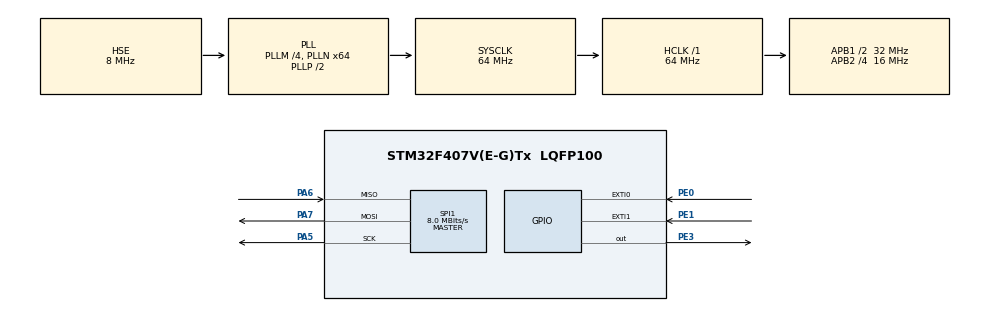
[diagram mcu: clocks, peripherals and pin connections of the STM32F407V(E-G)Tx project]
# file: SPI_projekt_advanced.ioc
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Mcu.Family=STM32F4
Mcu.Name=STM32F407V(E-G)Tx
Mcu.Package=LQFP100
NVIC.EXTI0_IRQn=true\:0\:0\:false\:false\:true\:true\:true\:true
NVIC.EXTI1_IRQn=true\:0\:0\:false\:false\:true\:true\:true\:true
NVIC.PriorityGroup=NVIC_PRIORITYGROUP_0
NVIC.SPI1_IRQn=true\:0\:0\:false\:false\:true\:true\:true\:true
PA5.Mode=Full_Duplex_Master
PA5.Signal=SPI1_SCK
PA6.Mode=Full_Duplex_Master
PA6.Signal=SPI1_MISO
PA7.Mode=Full_Duplex_Master
PA7.Signal=SPI1_MOSI
PE0.Signal=GPXTI0
PE1.Signal=GPXTI1
PE3.PinState=GPIO_PIN_SET
PE3.Signal=GPIO_Output
PH0-OSC_IN.Mode=HSE-External-Oscillator
PH0-OSC_IN.Signal=RCC_OSC_IN
PH1-OSC_OUT.Mode=HSE-External-Oscillator
PH1-OSC_OUT.Signal=RCC_OSC_OUT
ProjectManager.HeapSize=0x200
ProjectManager.StackSize=0x400
ProjectManager.TargetToolchain=STM32CubeIDE
RCC.48MHZClocksFreq_Value=18285714.285714287
RCC.AHBFreq_Value=64000000
RCC.APB1CLKDivider=RCC_HCLK_DIV2
RCC.APB1Freq_Value=32000000
RCC.APB1TimFreq_Value=64000000
RCC.APB2CLKDivider=RCC_HCLK_DIV4
RCC.APB2Freq_Value=16000000
RCC.APB2TimFreq_Value=32000000
RCC.CortexFreq_Value=64000000
RCC.HCLKFreq_Value=64000000
RCC.HSE_VALUE=8000000
RCC.HSI_VALUE=16000000
RCC.LSE_VALUE=32768
RCC.PLLM=4
RCC.PLLN=64
RCC.PLLQ=7
RCC.PLLSourceVirtual=RCC_PLLSOURCE_HSE
RCC.SYSCLKFreq_VALUE=64000000
RCC.SYSCLKSource=RCC_SYSCLKSOURCE_PLLCLK
RCC.VCOOutputFreq_Value=128000000
SPI1.CalculateBaudRate=8.0 MBits/s
SPI1.Direction=SPI_DIRECTION_2LINES
SPI1.Mode=SPI_MODE_MASTER
SPI1.VirtualType=VM_MASTER
board=STM32F407G-DISC1

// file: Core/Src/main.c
/* USER CODE BEGIN Header */
/**
  ******************************************************************************
  * @file           : main.c
  * @brief          : Main program body
  ******************************************************************************
  * @attention
  *
  * Copyright (c) 2024 STMicroelectronics.
  * All rights reserved.
  *
  * This software is licensed under terms that can be found in the LICENSE file
  * in the root directory of this software component.
  * If no LICENSE file comes with this software, it is provided AS-IS.
  *
  ******************************************************************************
  */
/* USER CODE END Header */
#include "main.h"
#include "spi_funkcije.h"

SPI_HandleTypeDef hspi1;

void SystemClock_Config(void);
static void MX_GPIO_Init(void);
static void MX_SPI1_Init(void);
/* USER CODE BEGIN PFP */
uint8_t xData;
uint8_t yData;
uint8_t zData;

float zzData;
/* USER CODE END PFP */
uint8_t cnt;
/* USER CODE BEGIN 0 */
void HAL_GPIO_EXTI_Callback(uint16_t GPIO_Pin) {

	cnt++;

}
/* USER CODE END 0 */

int main(void)
{

  /* MCU Configuration--------------------------------------------------------*/

  /* Reset of all peripherals, Initializes the Flash interface and the Systick. */
  HAL_Init();

  /* Configure the system clock */
  SystemClock_Config();

  /* Initialize all configured peripherals */
  MX_GPIO_Init();
  MX_SPI1_Init();

  /* Infinite loop */
  /* USER CODE BEGIN WHILE */

  //Set upaj prvi registar
  uint8_t data;
  MEMS_Read(LIS302DL_WHO_AM_I_ADDR, &data);
  MEMS_Write(LIS302DL_CTRL_REG1_ADDR, 0x47);
//  MEMS_Write(LIS302DL_CTRL_REG2_ADDR, 0x00);
//
//  // use FF_WU_1 to trigger interrupt on INT1
//  MEMS_Write(LIS302DL_CTRL_REG3_ADDR, 0x01);
//
//  // enable interrupt on X high, Y high
//  MEMS_Write(LIS302DL_FF_WU_CFG1_REG_ADDR, 0xD5);
//
//  // free-fall/wake-up threshold (7 bit)
//  MEMS_Write(LIS302DL_FF_WU_THS1_REG_ADDR, 0x14);
//
//  // free-fall/wake-up duration (8 bit)
//  // Step 2.5 msec, from 0 to 637.5 msec if ODR=400Hz,
//  // else step 10 msec, from 0 to 2.55 sec when ODR=100Hz.
//  MEMS_Write(LIS302DL_FF_WU_DURATION1_REG_ADDR, 0x09);
  while (1)
  {
   MEMS_Read(LIS302DL_OUT_X_ADDR, &xData);
   MEMS_Read(LIS302DL_OUT_Y_ADDR, &yData);
   MEMS_Read(LIS302DL_OUT_Z_ADDR, &zData);

   zzData = zData * 18;

  }
  /* USER CODE END 3 */
}

void SystemClock_Config(void)
{
  RCC_OscInitTypeDef RCC_OscInitStruct = {0};
  RCC_ClkInitTypeDef RCC_ClkInitStruct = {0};

  /** Configure the main internal regulator output voltage
  */
  __HAL_RCC_PWR_CLK_ENABLE();
  __HAL_PWR_VOLTAGESCALING_CONFIG(PWR_REGULATOR_VOLTAGE_SCALE1);

  /** Initializes the RCC Oscillators according to the specified parameters
  * in the RCC_OscInitTypeDef structure.
  */
  RCC_OscInitStruct.OscillatorType = RCC_OSCILLATORTYPE_HSE;
  RCC_OscInitStruct.HSEState = RCC_HSE_ON;
  RCC_OscInitStruct.PLL.PLLState = RCC_PLL_ON;
  RCC_OscInitStruct.PLL.PLLSource = RCC_PLLSOURCE_HSE;
  RCC_OscInitStruct.PLL.PLLM = 4;
  RCC_OscInitStruct.PLL.PLLN = 64;
  RCC_OscInitStruct.PLL.PLLP = RCC_PLLP_DIV2;
  RCC_OscInitStruct.PLL.PLLQ = 7;
  if (HAL_RCC_OscConfig(&RCC_OscInitStruct) != HAL_OK)
  {
    Error_Handler();
  }

  /** Initializes the CPU, AHB and APB buses clocks
  */
  RCC_ClkInitStruct.ClockType = RCC_CLOCKTYPE_HCLK|RCC_CLOCKTYPE_SYSCLK
                              |RCC_CLOCKTYPE_PCLK1|RCC_CLOCKTYPE_PCLK2;
  RCC_ClkInitStruct.SYSCLKSource = RCC_SYSCLKSOURCE_PLLCLK;
  RCC_ClkInitStruct.AHBCLKDivider = RCC_SYSCLK_DIV1;
  RCC_ClkInitStruct.APB1CLKDivider = RCC_HCLK_DIV2;
  RCC_ClkInitStruct.APB2CLKDivider = RCC_HCLK_DIV4;

  if (HAL_RCC_ClockConfig(&RCC_ClkInitStruct, FLASH_LATENCY_2) != HAL_OK)
  {
    Error_Handler();
  }
}

static void MX_SPI1_Init(void)
{

  /* SPI1 parameter configuration*/
  hspi1.Instance = SPI1;
  hspi1.Init.Mode = SPI_MODE_MASTER;
  hspi1.Init.Direction = SPI_DIRECTION_2LINES;
  hspi1.Init.DataSize = SPI_DATASIZE_8BIT;
  hspi1.Init.CLKPolarity = SPI_POLARITY_LOW;
  hspi1.Init.CLKPhase = SPI_PHASE_1EDGE;
  hspi1.Init.NSS = SPI_NSS_SOFT;
  hspi1.Init.BaudRatePrescaler = SPI_BAUDRATEPRESCALER_2;
  hspi1.Init.FirstBit = SPI_FIRSTBIT_MSB;
  hspi1.Init.TIMode = SPI_TIMODE_DISABLE;
  hspi1.Init.CRCCalculation = SPI_CRCCALCULATION_DISABLE;
  hspi1.Init.CRCPolynomial = 10;
  if (HAL_SPI_Init(&hspi1) != HAL_OK)
  {
    Error_Handler();
  }

}

static void MX_GPIO_Init(void)
{
  GPIO_InitTypeDef GPIO_InitStruct = {0};

  /* GPIO Ports Clock Enable */
  __HAL_RCC_GPIOE_CLK_ENABLE();
  __HAL_RCC_GPIOH_CLK_ENABLE();
  __HAL_RCC_GPIOA_CLK_ENABLE();

  /*Configure GPIO pin Output Level */
  HAL_GPIO_WritePin(GPIOE, GPIO_PIN_3, GPIO_PIN_SET);

  /*Configure GPIO pin : PE3 */
  GPIO_InitStruct.Pin = GPIO_PIN_3;
  GPIO_InitStruct.Mode = GPIO_MODE_OUTPUT_PP;
  GPIO_InitStruct.Pull = GPIO_NOPULL;
  GPIO_InitStruct.Speed = GPIO_SPEED_FREQ_LOW;
  HAL_GPIO_Init(GPIOE, &GPIO_InitStruct);

  /*Configure GPIO pins : PE0 PE1 */
  GPIO_InitStruct.Pin = GPIO_PIN_0|GPIO_PIN_1;
  GPIO_InitStruct.Mode = GPIO_MODE_IT_RISING;
  GPIO_InitStruct.Pull = GPIO_NOPULL;
  HAL_GPIO_Init(GPIOE, &GPIO_InitStruct);

  /* EXTI interrupt init*/
  HAL_NVIC_SetPriority(EXTI0_IRQn, 0, 0);
  HAL_NVIC_EnableIRQ(EXTI0_IRQn);

  HAL_NVIC_SetPriority(EXTI1_IRQn, 0, 0);
  HAL_NVIC_EnableIRQ(EXTI1_IRQn);

}

void Error_Handler(void)
{
  __disable_irq();
  while (1)
  {
  }
}
